# NANO103AE_v1 register map
File version: 1.0
Registers are 32-bit, read-write, reset 0x0 unless marked. A register's access mark holds for its fields unless they carry their own. Offsets are from the block's base; [hi:lo] are bit positions.

## WDT — WDT Register Map
Base 0x40004000
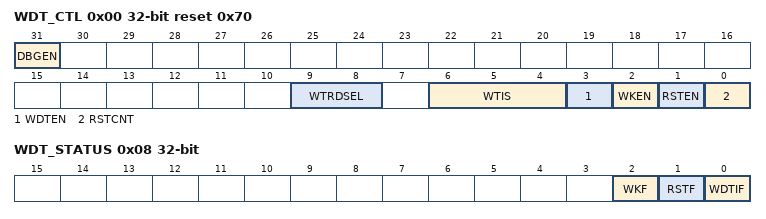
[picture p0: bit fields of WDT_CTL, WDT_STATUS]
0x00 WDT_CTL reset 0x70 — Watchdog Timer Control Register
  [31] DBGEN — WDT Debug Mode Enable Control (Write Protect)
    0=WDT stopped counting if system is in Debug mode; 1=WDT still counted even system is in Debug mode
  [9:8] WTRDSEL — Watchdog Timer Reset Delay Selection. When watchdog time-out happened, software has a time named watchdog reset delay period to clear watchdog timer to prevent watchdog reset happened. Software can select a suitable value of watchdog reset delay period for different watchdog time-out period. Note: This bit will be reset if watchdog reset happened
    0=Watchdog reset delay period is 1026 watchdog clock; 1=Watchdog reset delay period is 130 watchdog clock; 2=Watchdog reset delay period is 18 watchdog clock; 3=Watchdog reset delay period is 3 watchdog clock
  [6:4] WTIS — Watchdog Timer Interval Selection(Write Protect). Please refer to open lock sequence to program it. The three bits select the time-out interval for the Watchdog timer. This count is free running counter. Please refer toTable6.111.
  [3] WDTEN — Watchdog Timer EnableBit(Write Protect). Please refer to open lock sequence to program it.
    0=Watchdog timer Disabled (this action will reset the internal counter); 1=Watchdog timer Enabled
  [2] WKEN — Watchdog Timer Wake-up Function EnableBit(Write Protect). Please refer to open lock sequence to program it.
    0=Watchdog timer Wake-up CPU function Disabled; 1=Wake-up function Enabled so that Watchdog timer time-out can wake up CPU from Power-down mode
  [1] RSTEN — Watchdog Timer Reset Function EnableBit (Write Protect). Please refer to open lock sequence to program it. Setting this bit will enable the Watchdog timer reset function.
    0=Watchdog timer reset function Disabled; 1=Watchdog timer reset function Enabled
  [0] RSTCNT — Reset Watchdog TimerCounter (Write Protect). Please refer to open lock sequence to program it. Setting this bit will reset the Watchdog timer counter. Note: This bit will be auto cleared after 1 PCLK clock cycle.
    0=No effect; 1=Reset the contents of the Watchdog timer
0x04 WDT_INTEN — Watchdog Timer Interrupt Enable Register
  [0] WDTIEN — Watchdog Timer Time-out Interrupt EnableBit
    0=Watchdog timer time-out interrupt Disabled; 1=Watchdog timer time-out interrupt Enabled
0x08 WDT_STATUS — Watchdog Timer Status Register
  [2] WKF — Watchdog Timer Wake-up StatusFlag. If Watchdog timer causes system to wake up from Power-down mode, this bit will be set to 1. It must be cleared by software with a write "1" to this bit. Note1: When system in Power-down mode and watchdog time-out, hardware will set WKF and WDTIF. Note2: After one engine clock, this bit can be cleared by writing "1" to it
    0=Watchdog timer does not cause system wake-up; 1=Wake system up from Power-down mode by Watchdog time-out
  [1] RSTF — Watchdog Timer Reset StatusFlag. When the Watchdog timer initiates a reset, the hardware will set this bit. This flag can be read by software to determine the source of reset. Software is responsible to clear it manually by writing "1" to it. If RSTEN is disabled, then the Watchdog timer has no effect on this bit. Note: This bit is read only, but can be cleared by writing "1" to it.
    0=Watchdog timer reset did not occur; 1=Watchdog timer reset occurred
  [0] WDTIF — Watchdog Timer Time-out Interrupt StatusFlag. If the Watchdog timer time-out interrupt is enabled, then the hardware will set this bit to indicate that the Watchdog timer time-out interrupt has occurred. If the Watchdog timer time-out interrupt is not enabled, then this bit indicates that a time-out period has elapsed. Note:This bit is read only, but can be cleared by writing "1" to it.
    0=Watchdog timer time-out interrupt did not occur; 1=Watchdog timer time-out interrupt occurred
